# soc_aon_secure register map
Vendor: Texas Instruments
Peripheral module from a debugger description file (folder CC35X1).
Registers are 32-bit, access per field, reset 0x0 unless marked. A register's access mark holds for its fields unless they carry their own. Offsets are as the file gives them; lines under a group give offsets from that group; [hi:lo] are bit positions; {n}, {i} and the like mark numbered series; 'fields as' and 'values as' point back to an identical list; <NAME> marks a mode.

## soc_aon_secure (part 1 of 3)
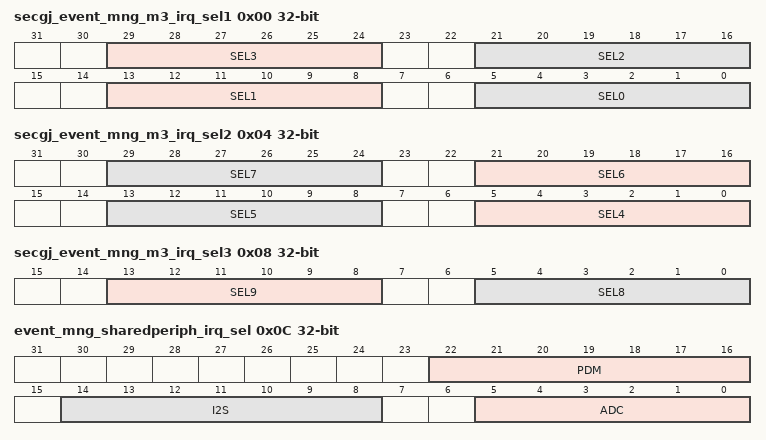
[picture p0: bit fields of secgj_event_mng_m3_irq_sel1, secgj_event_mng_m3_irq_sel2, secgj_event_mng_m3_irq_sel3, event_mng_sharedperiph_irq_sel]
0x00 secgj_event_mng_m3_irq_sel1 — M3 Event MUXs Selectors. One of three registers that contain selectors to M3 events. There are 10 event MUXs for M3. The selected event goes to ELP module as a wakeup event. INTERNAL NOTES: Event Manager DD - CORE 10 MUXs Selector Table [Confluence][https://confluence.itg.ti.com/display/WNG/Event+Manager+DD#EventManagerDD-CORE10MUXSelectorTable]
  [29:24] SEL3 rw — M3 Event Select Mux. This field selects 4th MUX output to M3 IRQ trough ELP as a wakeup event.
  [21:16] SEL2 rw — M3 Event Select Mux. This field selects 3rd MUX output to M3 IRQ trough ELP as a wakeup event.
  [13:8] SEL1 rw — M3 Event Select Mux. This field selects 2nd MUX output to M3 IRQ trough ELP as a wakeup event.
  [5:0] SEL0 rw — M3 Event Select Mux. This field selects 1st MUX output to M3 IRQ trough ELP as a wakeup event.
0x04 secgj_event_mng_m3_irq_sel2 — M3 Event MUXs Selectors. One of three registers that contain selectors to M3 events. There are 10 event MUXs for M3. The selected event goes to ELP module as a wakeup event. INTERNAL NOTES: Event Manager DD - CORE 10 MUXs Selector Table [Confluence][https://confluence.itg.ti.com/display/WNG/Event+Manager+DD#EventManagerDD-CORE10MUXSelectorTable]
  [8n-27:8n-32] SEL{n} rw (n=4..7) — M3 Event Select Mux. This field selects {n+1}th MUX output to M3 IRQ trough ELP as a wakeup event.
0x08 secgj_event_mng_m3_irq_sel3 — M3 Event MUXs Selectors. One of three registers that contain selectors to M3 events. There are 10 event MUXs for M3. The selected event goes to ELP module as a wakeup event. INTERNAL NOTES: Event Manager DD - CORE 10 MUXs Selector Table [Confluence][https://confluence.itg.ti.com/display/WNG/Event+Manager+DD#EventManagerDD-CORE10MUXSelectorTable]
  [13:8] SEL9 rw — M3 Event Select Mux. This field selects 10th MUX output to M3 IRQ trough ELP as a wakeup event.
  [5:0] SEL8 rw — M3 Event Select Mux. This field selects 9th MUX output to M3 IRQ trough ELP as a wakeup event.
0x0C event_mng_sharedperiph_irq_sel — Shared Peripherals Event MUXs Selectors. This register selects events to ADC, I2S and PDM. INTERNAL NOTE: Shared Peripherals selector table- [Confluence][https://confluence.itg.ti.com/display/WNG/Event+Manager+DD#EventManagerDD-SharedPeripheralsMUXSelectorTable]
  [22:16] PDM rw — PDM Event Selector. This field selects event to PDM. INTERNAL NOTE: PDM event selector table: [Confluence][https://confluence.itg.ti.com/display/WNG/Event+Manager+DD#EventManagerDD-PDMEventSelectorTable]
  [14:8] I2S rw — I2S Event Selector. This field selects event to I2S. INTERNAL NOTE: I2S event selector table: [Confluence][https://confluence.itg.ti.com/display/WNG/Event+Manager+DD#EventManagerDD-I2SEventSelectorTable]
  [5:0] ADC rw — ADC Event Selector. This field selects event to ADC. INTERNAL NOTE: ADC event selector table: [Confluence][https://confluence.itg.ti.com/display/WNG/Event+Manager+DD#EventManagerDD-ADCEventSelectorTable]
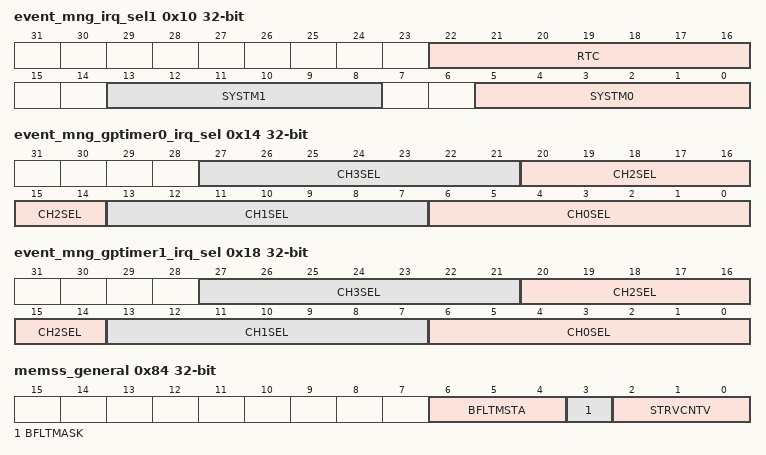
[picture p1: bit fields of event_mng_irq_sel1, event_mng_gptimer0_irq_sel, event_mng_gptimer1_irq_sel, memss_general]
0x10 event_mng_irq_sel1 — Timers Event MUXs Selectors. This register selects events to SYSTIMER and RTC. There are two MUXs of SYSTIMER and one for RTC.
  [22:16] RTC rw — RTC Event Selector. This field selects event to RTC. INTERNAL NOTE: RTC event selector table: [Confluence][https://confluence.itg.ti.com/display/WNG/Event+Manager+DD#EventManagerDD-RTCEventSelectorTable]
  [13:8] SYSTM1 rw — SYSTIMER Event 2nd Selector. This field selects event to SYSTIMER. INTERNAL NOTE: SYSTIMER event selector table: [Confluence][https://confluence.itg.ti.com/display/WNG/Event+Manager+DD#EventManagerDD-SysTimerEventSelectorTable]
  [5:0] SYSTM0 rw — SYSTIMER Event 1st Selector. This field selects event to SYSTIMER. INTERNAL NOTE: SYSTIMER event selector table: [Confluence][https://confluence.itg.ti.com/display/WNG/Event+Manager+DD#EventManagerDD-SysTimerEventSelectorTable]
0x14 event_mng_gptimer0_irq_sel — GPTIMER0 Channels Event MUXs Selectors. This register selects events to GPTIMER0. There are 4 event MUXs for GPTIMER Channels. INTERNAL NOTE: GPTIMER0 selector table- [Confluence][https://confluence.itg.ti.com/display/WNG/Event+Manager+DD#EventManagerDD-GPTIMER0EventSelectorTable]
  [7n+6:7n] CH{n}SEL rw (n=0..3) — This field selects MUX output to CH{n} of GPTIMER0 IRQ.
0x18 event_mng_gptimer1_irq_sel — GPTIMER1 Event MUXs Selectors. This register selects events to GPTIMER1. There are 4 event MUXs for GPTIMER Channels. INTERNAL NOTE: GPTIMER1 selector table- [Confluence][https://confluence.itg.ti.com/display/WNG/Event+Manager+DD#EventManagerDD-GPTIMER1EventSelectorTable]
  [7n+6:7n] CH{n}SEL rw (n=0..3) — This field selects MUX output to CH{n} of GPTIMER1 IRQ.
0x1C doorbell0_m2_clr — Doorbell 0 M33 Clear Register
  [0] CLR wo — M33 to clear the IRQ after handled the massage from M3. type : Write-Clear
0x20 doorbell0_m2_pulse — Doorbell 0 M33 Set Register.
  [0] SET wo — M33 to generate IRQ towards M3 after writing the message. type: Write-Clear
0x24 doorbell0_m2_lockbit — Doorbell 0 M33 Lock Bit.
  [1:0] LOCKBIT rw — Lock Bit. S/w attempt to lock upon read. if lock obtained, value set to 2 by h/w. M33 always looses to M3 Reading value: 0. not taken 1. taken by M3 2. taken by M33 (should wr IRQ afterwards) 3. invalid. generating the IRQ towards M3 clears the lock. Writing '00' also release the lock. '01' means lock obtained by receiver side Type: Write-Read-Clear
0x28 doorbell1_m2_clr — Doorbell 1 M33 Clear Register
  fields as doorbell0_m2_clr
0x2C doorbell1_m2_pulse — Doorbell 1 M33 Set Register.
  fields as doorbell0_m2_pulse
0x30 doorbell1_m2_lockbit — Doorbell 1 M33 Lock Bit.
  fields as doorbell0_m2_lockbit
0x34 doorbell4_m2_clr — Doorbell 4 M33 Clear Register
  fields as doorbell0_m2_clr
0x38 doorbell4_m2_pulse — Doorbell 4 M33 Set Register.
  fields as doorbell0_m2_pulse
0x3C doorbell4_m2_lockbit — Doorbell 4 M33 Lock Bit.
  fields as doorbell0_m2_lockbit
0x40 doorbell5_m2_clr — Doorbell 5 M33 Clear Register
  fields as doorbell0_m2_clr
0x44 doorbell5_m2_pulse — Doorbell 5 M33 Set Register.
  fields as doorbell0_m2_pulse
0x48 doorbell5_m2_lockbit — Doorbell 5 M33 Lock Bit.
  fields as doorbell0_m2_lockbit
0x4C secgr_cmem_int_addr_start reset not defined — CODE Memory MEMSS Start Address. CMEM Start Address-also define S/NS region split. split is in 1k resolution
  [31:12] ADDR rw — CMEM Start Address-also define S/NS region split. split is in 1k resolution
0x50 secgr_cmem_int_addr_end reset not defined — CODE Memory MEMSS End Address. CMEM end Address-also define S/NS region split
  [31:12] ADDR rw — CMEM end Address-also define S/NS region split
0x54 secgr_dmem_int_addr_start reset not defined — DATA Memory MEMSS Start Address. DMEM Start Address-also define S/NS region split
  [31:12] ADDR rw — DMEM Start Address-also define S/NS region split
0x58 secgr_dmem_int_addr_end reset not defined — DATA Memory MEMSS End Address. DMEM end Address-also define S/NS region split
  [31:12] ADDR rw — DMEM end Address-also define S/NS region split
0x64 secgr_tcm_data_int_addr_start reset not defined — TCM DATA Memory MEMSS Start Address. TCM data Start Address-also define S/NS region split
  [31:10] ADDR rw — TCM data Start Address-also define S/NS region split
0x68 secgr_tcm_data_int_addr_end reset not defined — TCM DATA Memory MEMSS End Address. TCM data end Address-also define S/NS region split
  [31:10] ADDR rw — TCM data end Address-also define S/NS region split
0x7C secured_gpio_evt_sts_0 ro — Secured GPIO Event Status, 1st Register. 45 bits status over two registers.
  [31:0] STA31TO0 — Secured event status , first 32 bits. ([31:0])
0x80 secured_gpio_evt_sts_1 ro — Secured GPIO Event Status, 2nd Register. 45 bits status over two registers.
  [12:0] STA44TO32 — Secured event status , 13 MSBs. ([44:32])
0x84 memss_general — MEMSS General Control Register. This register controls starvation mechanism counter value and MEMSS bus fault mask.
  [6:4] BFLTMSTA ro — Bus Fault Masked Status. Out of Memory Index: 0. No error 1. M33 Code 2. M33 Data #1 + #2 3. M3 Code 4. M3 Data 5. M3 PRAM 6. BLE Code 7. Global OCP
  [3] BFLTMASK rw — MEMSS Bus Fault Mask 1. Mask 0. Do not mask
  [2:0] STRVCNTV rw — Starvation Counter Value Configuration. That value reflect how long writing to mailbox can be delayed.
0x88 memss_bus_fault_raw_status ro — MEMSS General Control Register. This is a status register for bus fault raw status.
  [2:0] BFLTRWSTA — Bus Fault Raw Status. Error indication from memss. Out of Memory Index: 0. No error 1. M33 Code 2. M33 Data #1 + #2 3. M3 Code 4. M3 Data 5. M3 PRAM 6. BLE Code 7. Global OCP Type: Read-Clear
0x90 spare — Spare Register. This is a spare register in M33S aperture.
  [3:0] BF rw — Spare Field. Non-locked , M33S aperture.
0x9C secgt_vtor_s — M33 Secure Vector Table Base Address.
  [31:7] ADDR rw — init VTOR Secured Address.
0xA0 secgu_vtor_ns — M33 Non-Secure Vector Table Base Address.
  [31:7] ADDR rw — init VTOR non Secured address
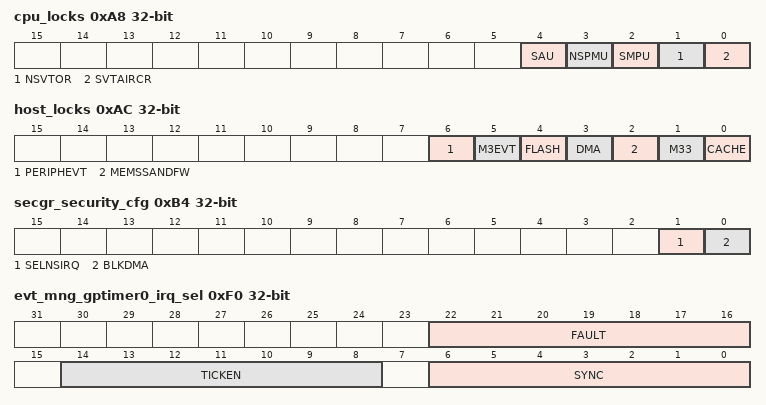
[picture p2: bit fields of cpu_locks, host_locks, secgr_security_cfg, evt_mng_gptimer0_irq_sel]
0xA8 cpu_locks — CPU Locks. This register contain 5 locks. Issued to M33 Cortex and used to lock internal cortex registers. LOCKSVTAIRCR, LOCKNSVTOR, LOCKSMPU, LOCKNSMPU, LOCKSAU.
  [4] SAU rw — Locking this Cortex internal configuration
  [3] NSPMU rw — Locking this Cortex internal configuration
  [2] SMPU rw — Locking this Cortex internal configuration
  [1] NSVTOR rw — Locking this Cortex internal configuration
  [0] SVTAIRCR rw — Locking this Cortex internal configuration
0xAC host_locks access not given — Host Lock Signals. lock once. Do Not lock until written. When written Locked immediately, cleared only at soc aon reset or por reset. These are host security lock configurations (some can be also locked by TI)
  [6] PERIPHEVT — Locking the firewall configurations of: HIF, CORE, CORE AON, HSM, shared Periphs
  [5] M3EVT — Locking the configurations of M3 Events
  [4] FLASH — Locking the configurations of On The Fly Enc/Decryption Module Region Related Registers (four registers per region, four regions)
  [3] DMA — Locking the configurations of System DMA
  [2] MEMSSANDFW — Locking the configurations of Memory Sub System
  [1] M33 — Locking the configurations of Host MCU, both Secured and non Secured
  [0] CACHE — Locking the configurations of ICACHE
0xB0 host_boot_done access not given — Host Boot Done 1 lock. Write once. Asserted by FW by the end of soc boot done Or in elevated mode By either by TI of by the host and indicates device exit from secure boot mode. this signal also locks host security configurations , Locked immediately , cleared only at soc aon reset or por reset
  [0] DONE — Locking host security configurations
0xB4 secgr_security_cfg — Security Configurations.
  [1] SELNSIRQ rw — This field determine whether the 4 SW interrupts MSbits will be owned by secured/non secured. 0. Non-Secured 1. Secured
  [0] BLKDMA rw — This Field blocks the uDMA transactions to CMEM. 0. un-Block 1. Block
0xB8 db_m33_sec_imask reset 0xFFFF0 (reset mask 0xFFFFFFF0) — Doorbell M33 Secured IMASK. Mask Event. 0. CLR - Clear Interrupt Mask 1. SET - Set Interrupt Mask
  [3:0] IMASK rw — Bits division to events: bit [3] - doorbell 5 M3 IRQ bit [2] - doorbell 4 M3 IRQ bit [1] - doorbell 1 M3 IRQ bit [0] - doorbell 0 M3 IRQ
0xBC db_m33_sec_iset_evt_mng — Doorbell M33 Secured ISET. Sets event in RIS Write 0 - NO_EFFECT - Writing 0 has no effect Write 1 - SET - Sets interrupt
  [3:0] ISET wo — Bits division to events: bit [3] - doorbell 5 M3 IRQ bit [2] - doorbell 4 M3 IRQ bit [1] - doorbell 1 M3 IRQ bit [0] - doorbell 0 M3 IRQ Type: Write-Clear
0xC0 db_m33_sec_iclr_evt_mng — Doorbell M33 Secured ICLR. Clears event in RIS Write 0 - NO_EFFECT - Writing 0 has no effect Write 1 - CLR - Clears the Event
  [3:0] ICLR wo — Bits division to events: bit [3] - doorbell 5 M3 IRQ bit [2] - doorbell 4 M3 IRQ bit [1] - doorbell 1 M3 IRQ bit [0] - doorbell 0 M3 IRQ Type: Write-Clear
0xC4 db_m33_sec_imset_evt_mng — Doorbell M33 Secured IMSET. Sets Event Write 0 - NO_EFFECT - Writing 0 has no effect Write 1 - SET - Set interrupt mask
  [3:0] IMSET wo — Bits division to events: bit [3] - doorbell 5 M3 IRQ bit [2] - doorbell 4 M3 IRQ bit [1] - doorbell 1 M3 IRQ bit [0] - doorbell 0 M3 IRQ Type: Write-Clear
0xC8 db_m33_sec_imclr_evt_mng — Doorbell M33 Secured IMCLR. Clears Event Write 0 - NO_EFFECT - Writing 0 has no effect Write 1 - CLR - Clear interrupt mask
  [3:0] IMCLR wo — Bits division to events: bit [3] - doorbell 5 M3 IRQ bit [2] - doorbell 4 M3 IRQ bit [1] - doorbell 1 M3 IRQ bit [0] - doorbell 0 M3 IRQ Type: Write-Clear
0xCC db_m33_sec_ris_evt_mng ro — Doorbell M33 Secured RIS. Raw interrupt status for event. This bit is set to 1 when an event is received. when the corresponding bit in ICLR is set to 1, this bit will be cleared. Read 0 - CLR - Interrupt did not occur Read 1 - SET - Interrupt occurred
  [3:0] RIS — Bits division to events: bit [3] - doorbell 5 M3 IRQ bit [2] - doorbell 4 M3 IRQ bit [1] - doorbell 1 M3 IRQ bit [0] - doorbell 0 M3 IRQ
0xD0 db_m33_sec_mis_evt_mng ro — Doorbell M33 Secured MIS. Mask interrupt status for event Read 0 - CLR - Interrupt did not occur Read 1 - SET - Interrupt occurred
  [3:0] MIS — Bits division to events: bit [3] - doorbell 5 M3 IRQ bit [2] - doorbell 4 M3 IRQ bit [1] - doorbell 1 M3 IRQ bit [0] - doorbell 0 M3 IRQ
0xD4 error_m33_sec_imask reset 0xFFFF — M33 Secured Error IMASK. Mask Event. '0' - CLR - Clear Interrupt Mask '1' - SET - Set Interrupt Mask
  [7:0] IMASK rw — Bits division to events: bit[7] - CORE ELP WATCHDOG Timer bit[6:4] - SOC IC IRQs bit[3] - CORE to SDIO WATCHDOG bit[2] - PLL Unlock bit[1] - MEMss bus fault bit[0] - HSM fatal error
0xD8 error_m33_sec_iset_evt_mng — M33 Secured Error ISET. Sets event in RIS Write 0 - NO_EFFECT - Writing 0 has no effect Write 1 - SET - Sets interrupt
  [7:0] ISET wo — Bits division to events: bit[7] - CORE ELP WATCHDOG Timer bit[6:4] - SOC IC IRQs bit[3] - CORE to SDIO WATCHDOG bit[2] - PLL Unlock bit[1] - MEMss bus fault bit[0] - HSM fatal error Type: Write-Clear
0xDC error_m33_sec_iclr_evt_mng — M33 Secured Error ICLR. Clears event in RIS Write 0 - NO_EFFECT - Writing 0 has no effect Write 1 - CLR - Clears the Event
  [7:0] ICLR wo — Bits division to events: bit[7] - CORE ELP WATCHDOG Timer bit[6:4] - SOC IC IRQs bit[3] - CORE to SDIO WATCHDOG bit[2] - PLL Unlock bit[1] - MEMss bus fault bit[0] - HSM fatal error Type: Write-Clear
0xE0 error_m33_sec_imset_evt_mng — M33 Secured Error IMSET. Sets Event Write 0 - NO_EFFECT - Writing 0 has no effect Write 1 - SET - Set interrupt mask
  [7:0] IMSET wo — Bits division to events: bit[7] - CORE ELP WATCHDOG Timer bit[6:4] - SOC IC IRQs bit[3] - CORE to SDIO WATCHDOG bit[2] - PLL Unlock bit[1] - MEMss bus fault bit[0] - HSM fatal error Type: Write-Clear
0xE4 error_m33_sec_imclr_evt_mng — M33 Secured Error IMCLR. Clears Event Write 0 - NO_EFFECT - Writing 0 has no effect Write 1 - CLR - Clear interrupt mask
  [7:0] IMCLR wo — Bits division to events: bit[7] - CORE ELP WATCHDOG Timer bit[6:4] - SOC IC IRQs bit[3] - CORE to SDIO WATCHDOG bit[2] - PLL Unlock bit[1] - MEMss bus fault bit[0] - HSM fatal error Type: Write-Clear
0xE8 error_m33_sec_ris_evt_mng ro — M33 Secured Error RIS. Raw interrupt status for event. This bit is set to 1 when an event is received. when the corresponding bit in ICLR is set to 1, this bit will be cleared. Read 0 - CLR - Interrupt did not occur Read 1 - SET - Interrupt occurred
  [7:0] RIS — Bits division to events: bit[7] - CORE ELP WATCHDOG Timer bit[6:4] - SOC IC IRQs bit[3] - CORE to SDIO WATCHDOG bit[2] - PLL Unlock bit[1] - MEMss bus fault bit[0] - HSM fatal error
0xEC error_m33_sec_mis_evt_mng ro — M33 Secured Error MIS. Mask interrupt status for event Read 0 - CLR - Interrupt did not occur Read 1 - SET - Interrupt occurred
  [7:0] MIS — Bits division to events: bit[7] - CORE ELP WATCHDOG Timer bit[6:4] - SOC IC IRQs bit[3] - CORE to SDIO WATCHDOG bit[2] - PLL Unlock bit[1] - MEMss bus fault bit[0] - HSM fatal error
0xF0 evt_mng_gptimer0_irq_sel — GPTIMER0 Sync, Tick Enable and Fault Event MUXs Selectors. This register selects events to GPTIMER0. INTERNAL NOTE: GPTIMER0 selector table- [Confluence][https://confluence.itg.ti.com/display/WNG/Event+Manager+DD#EventManagerDD]
  [22:16] FAULT rw — Selects fault MUX output to GPTIMER0 IRQ
  [14:8] TICKEN rw — Selects tick enable MUX output to GPTIMER0 IRQ
  [6:0] SYNC rw — Selects sync MUX output to GPTIMER0 IRQ
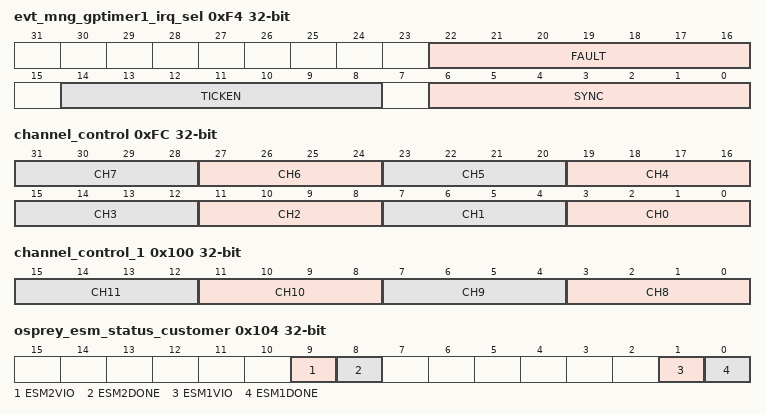
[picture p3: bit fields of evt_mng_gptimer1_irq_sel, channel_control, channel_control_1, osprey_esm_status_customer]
0xF4 evt_mng_gptimer1_irq_sel — GPTIMER1 Sync, Tick Enable and Fault Event MUXs Selectors. This register selects events to GPTIMER1. INTERNAL NOTE: GPTIMER0 selector table- [Confluence][https://confluence.itg.ti.com/display/WNG/Event+Manager+DD#EventManagerDD]
  fields as evt_mng_gptimer0_irq_sel
0xFC channel_control rw — Host DMA Channel Controlled by Defined Peripheral. The value of each fields concats with [HOST_DMA:JOBCTLCHx.SRCDSTCFG] (when x is channel num) if [CHCTL0.CHx] = 4 and [JOBCTLCHx.SRCDSTCFG] = 1 (value = 0100_1 = 9) then flow control signals of channel x are connected to periph number 9 flow control signals
  [4n+3:4n] CH{n} (n=0..7) — Channel {n} Control. Flow control signals: 22 HIF 21 Not Valid - PDM has only read 20 PDM 19 Not Valid - ADC has only read 18 ADC 17 MCAN 1 16 MCAN 0 15 SDIO TX 14 SDIO RX 13 SDMMC TX 12 SDMMC RX 11 I2C TX 10 I2C RX 9 I2C TX 8 I2C RX 7 SPI TX 6 SPI RX 5 SPI TX 4 SPI RX 3 UART TX 2 UART RX 1 UART TX 0 UART RX
0x100 channel_control_1 — Host DMA Channel Controlled by Defined Peripheral. The value of each fields concats with [HOST_DMA:JOBCTLCHx.SRCDSTCFG] (when x is channel num) if [CHCTL1.CHx] = 4 and [JOBCTLCHx.SRCDSTCFG] = 1 (value = 0100_1 = 9) then flow control signals of channel x are connected to periph number 9 flow control signals
  [4n-29:4n-32] CH{n} rw (n=8..11) — Channel {n} Control. Flow control signals: 22 HIF 21 Not Valid - PDM has only read 20 PDM 19 Not Valid - ADC has only read 18 ADC 17 MCAN 1 16 MCAN 0 15 SDIO TX 14 SDIO RX 13 SDMMC TX 12 SDMMC RX 11 I2C TX 10 I2C RX 9 I2C TX 8 I2C RX 7 SPI TX 6 SPI RX 5 SPI TX 4 SPI RX 3 UART TX 2 UART RX 1 UART TX 0 UART RX
0x104 osprey_esm_status_customer ro — Customer ESMs Status. status register , for each of the ESM (enable sequence monitor) what is the status (Done, violated, or None) Final ESM status for the entire ESM - ESM machine + magic value comparators
  [9] ESM2VIO — This field indicates that ESM1 is violated.
  [8] ESM2DONE — This field indicates that ESM2 is done.
  [1] ESM1VIO — This field indicates that ESM1 is violated.
  [0] ESM1DONE — This field indicates that ESM1 is done.
0x10C secgg_memss_cfg — MEMSS Configurations. Supported Memory configurations: Functional Modes: 0x0. Baseline 0x1. Extended M3 0x2. Extended throughput 0x3. Extended throughput + WIFI features 0x4. Extended Host Execution 0x5. Extended M33 Data Debug Modes (OCLA Memory): 0x6. Core debug (<M33 Data) 0x7. Core debug Extended throughput (<M33 Data <M3 Exec) 0x8. Core debug PHY only (<M3,M33 Data) 0x9. Host debug (<M3 Exec) 0xA. Host debug extended Host Execution 0xB. Host debug extended M33 Data
  [3:0] MODE rw — MEMSS mode of bank ownership
0x138 secured_gpio_mis_0 ro — Secured Gpio MIS.
  [31:0] _31TO0 — 32 LSBs of MIS. (45 Total)
0x13C secured_gpio_mis_1 ro — Secured Gpio MIS.
  [12:0] _44TO32 — 13 MSBs of MIS. (45 Total)
0x140 secured_gpio_func_0 rw — Secured GPIO Functional Mask. 0. Mask 1. Un-Mask
  [31:0] MASK31TO0 — 32 LSBs of MASK. (45 Total)
0x144 secured_gpio_func_1 — Secured GPIO Functional Mask. 0. Mask 1. Un-Mask
  [12:0] MASK44TO32 rw — 13 MSBs of MASK. (45 Total)
0x148 m33s_spare — Spare Reg, M33S Aperture. non-locked.
  [3:0] BF rw — M33S spare register. not locked.
0x14C secgk_esm1_2nd_magic_val — ESM1 2nd Magic Value. This value is compared to hard coded value and unmask ESM only when value is matched. This additional compare allow additional protection on ESM and also allow vendor to unmask ESM only at the end of vendor secure boot (SBL) is completed
  [7:0] MGCVAL rw — ESM 2nd magic value
0x150 secgk_esm2_2nd_magic_val — ESM2 2nd Magic Value. This value is compared to hard coded value and unmask ESM only when value is matched. This additional compare allow additional protection on ESM and also allow vendor to unmask ESM only at the end of vendor secure boot (SBL) is completed
  [7:0] MGCVAL rw — ESM 2nd magic value
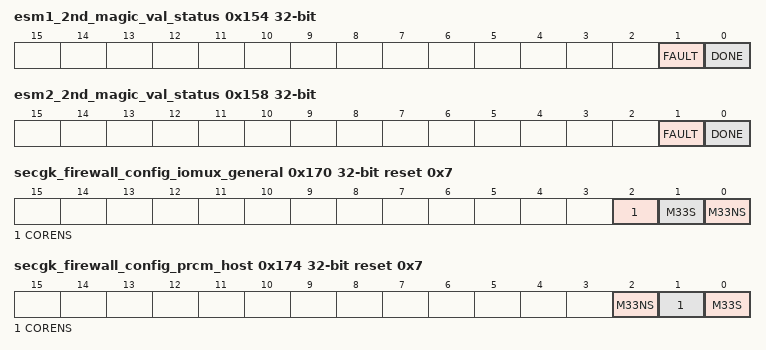
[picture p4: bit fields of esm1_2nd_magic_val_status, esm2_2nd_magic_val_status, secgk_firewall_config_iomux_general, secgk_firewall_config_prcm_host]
0x154 esm1_2nd_magic_val_status ro — ESM1 2nd Magic Value Status. ESM magic value match indication.
  [1] FAULT — ESM 2nd magic val fault ( note: indicates fault before a write to the magic val register)
  [0] DONE — ESM 2nd magic val match
0x158 esm2_2nd_magic_val_status ro — ESM2 2nd Magic Value. ESM magic value match indication.
  fields as esm1_2nd_magic_val_status
0x15C secgk_firewall_config_host_bypass reset 0x1 — HOST FW Bypass.
  [0] BYPASS rw — bypass the following module's firewall configuration: IOMUX_COMMON_SEL PRCM_AON_HOST PRCM_AON_COMMON SCRATCHPAD PLLSHARING SOC_IC SOC_AON_M33_S SOC_AON_M33_NS SOC_AAON_M33_S SOC_AAON_M33_NS RTC XIP_OSPI XIP_OSPI_INDAC XIP_GENERAL XIP_UDMA_SEC XIP_UDMA_NON_SEC OTFDE_REGION0-3 HOST_DMA_GENERAL_CFG
0x160 secgk_firewall_config_dma_bypass reset 0x1 — DMA FW BYPASS
  [0] BYPASS rw — Bypass the firewall configuration for HOST_DMA module
0x164 secgk_firewall_config_peripherals_bypass reset 0x1 — Peripheral Firewall Bypass.
  [0] BYPASS rw — bypass the following module's firewall configuration: HIF HSM CORE_AON I2C0/1 SPI0/1 UART0/1 GPTIMER0/1 I2S PDM CAN ADC SDMMC SDIO
0x168 secgk_firewall_config_m33_bypass reset 0x1 — HOST MCU Firewall Bypass
  [0] BYPASS rw — bypass the firewall configuration for HOST MCU module.
0x16C secgk_firewall_config_memss_bypass reset 0x1 — MEMSS Firewall Bypass
  [0] BYPASS rw — bypass the Firewall configuration for MEMSS module.
0x170 secgk_firewall_config_iomux_general reset 0x7 — IOMUX General firewall access permission for 3 controller id : 0 - M33 Non Secured 1 - M33 Secured 2 - Core (Non Secure)
  [2] CORENS rw — Controller Core Non Secured: '0' - access not allowed '1' - access allowed
  [1] M33S rw — Controller M33 Secured: '0' - access not allowed '1' - access allowed
  [0] M33NS rw — Controller M33 None Secured: '0' - access not allowed '1' - access allowed
0x174 secgk_firewall_config_prcm_host reset 0x7 — PRCM_HOST firewall access permission for 3 controller id : 0 - M33 Non Secured 1 - M33 Secured 2 - Core (Non Secure)
  [2] M33NS rw — Controller M33 None Secured: '0' - access not allowed '1' - access allowed
  [1] CORENS rw — Controller Core Non Secured: '0' - access not allowed '1' - access allowed
  [0] M33S rw — Controller M33 Secured: '0' - access not allowed '1' - access allowed
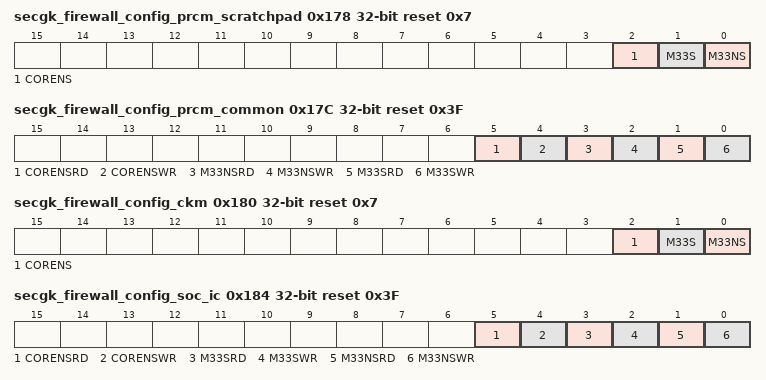
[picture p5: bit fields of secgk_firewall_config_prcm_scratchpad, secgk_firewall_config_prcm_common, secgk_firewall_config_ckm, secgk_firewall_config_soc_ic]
0x178 secgk_firewall_config_prcm_scratchpad reset 0x7 — M33 SCRATCHPAD firewall access permission for 3 controller id : 0 - M33 Non Secured 1 - M33 Secured 2 - Core (Non Secure)
  fields as secgk_firewall_config_iomux_general
0x17C secgk_firewall_config_prcm_common reset 0x3F — PRCM_COMMON firewall access permission for 3 controller id : 0 - M33 Non Secured 1 - M33 Secured 2 - Core (Non Secure)
  [5] CORENSRD rw — Controller Core Non Secured: '0' - access not allowed '1' - access allowed
  [4] CORENSWR rw — Controller Core Non Secured: '0' - access not allowed '1' - access allowed
  [3] M33NSRD rw — Controller M33 None Secured: '0' - access not allowed '1' - access allowed
  [2] M33NSWR rw — Controller M33 None Secured: '0' - access not allowed '1' - access allowed
  [1] M33SRD rw — Controller M33 Secured: '0' - access not allowed '1' - access allowed
  [0] M33SWR rw — Controller M33 Secured: '0' - access not allowed '1' - access allowed
0x180 secgk_firewall_config_ckm reset 0x7 — CKM firewall access permission for 3 controller id : 0 - M33 Non Secured 1 - M33 Secured 2 - Core (Non Secure)
  fields as secgk_firewall_config_iomux_general
0x184 secgk_firewall_config_soc_ic reset 0x3F — SOC_IC firewall access permission for 3 controller id : 0 - M33 Non Secured 1 - M33 Secured 2 - Core (Non Secure)
  [5] CORENSRD rw — Controller Core Non Secured: '0' - access not allowed '1' - access allowed
  [4] CORENSWR rw — Controller Core Non Secured: '0' - access not allowed '1' - access allowed
  [3] M33SRD rw — Controller M33 Secured: '0' - access not allowed '1' - access allowed
  [2] M33SWR rw — Controller M33 Secured: '0' - access not allowed '1' - access allowed
  [1] M33NSRD rw — Controller M33 None Secured: '0' - access not allowed '1' - access allowed
  [0] M33NSWR rw — Controller M33 None Secured: '0' - access not allowed '1' - access allowed
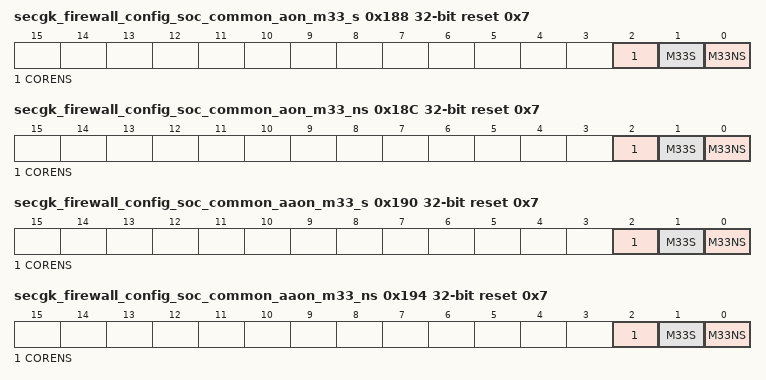
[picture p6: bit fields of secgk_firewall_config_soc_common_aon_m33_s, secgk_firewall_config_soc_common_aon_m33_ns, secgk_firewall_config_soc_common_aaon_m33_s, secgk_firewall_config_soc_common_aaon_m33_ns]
0x188 secgk_firewall_config_soc_common_aon_m33_s reset 0x7 — AON_M33_S firewall access permission for 3 controller id : 0 - M33 Non Secured 1 - M33 Secured 2 - Core (Non Secure)
  fields as secgk_firewall_config_iomux_general
0x18C secgk_firewall_config_soc_common_aon_m33_ns reset 0x7 — AON_M33_NS firewall access permission for 3 controller id : 0 - M33 Non Secured 1 - M33 Secured 2 - Core (Non Secure)
  fields as secgk_firewall_config_iomux_general
0x190 secgk_firewall_config_soc_common_aaon_m33_s reset 0x7 — AAON_M33_S firewall access permission for 3 controller id : 0 - M33 Non Secured 1 - M33 Secured 2 - Core (Non Secure)
  fields as secgk_firewall_config_iomux_general
0x194 secgk_firewall_config_soc_common_aaon_m33_ns reset 0x7 — AAON_M33_NS firewall access permission for 3 controller id : 0 - M33 Non Secured 1 - M33 Secured 2 - Core (Non Secure)
  fields as secgk_firewall_config_iomux_general
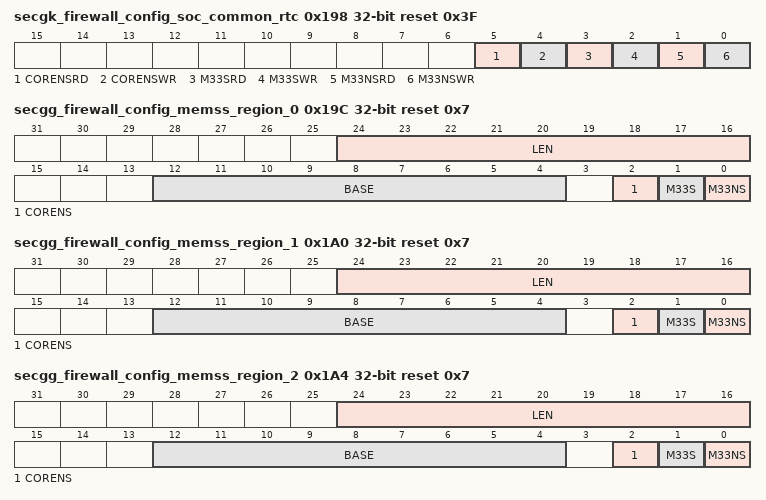
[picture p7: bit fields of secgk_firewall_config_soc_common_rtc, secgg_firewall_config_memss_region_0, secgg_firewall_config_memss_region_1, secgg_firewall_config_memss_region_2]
0x198 secgk_firewall_config_soc_common_rtc reset 0x3F — RTC firewall access permission for 3 controller id : 0 - M33 Non Secured 1 - M33 Secured 2 - Core (Non Secure)
  fields as secgk_firewall_config_soc_ic
0x19C secgg_firewall_config_memss_region_0 reset 0x7 — MEMSS region 0 firewall access permission for 3 controller id : 0 - M33 Non Secured (valid only in privilege mode) 1 - M33 Secured (valid only in privilege mode) 2 - Core (Non Secure) MEMSS address space: 0x41C00000 - 0x41DFFFFF for Memss the base address for security firewalls is 0x41c78000 ( M33 Data Ram from global port access) max window size is 512Kb
  [24:16] LEN rw — address base with 1K granularity : address base len for firewall is the offset from the region's base address indicated in the same region field describing the end of a firewall window that has a certain access rules (R/W Permission) for each controller-id MEMSS address space: 0x41C00000 - 0x41DFFFFF for Memss the base address for security firewalls is 0x41c78000 ( M33 Data Ram from global port access) max window size is 512Kb example: worker base address: 0x41C00000 current address to access: 0x41C01514 region_base_address: 0x4 region_base_address_len: 0x2 --> (region_base_address + region_base_address_len) --> 0x4+0x2 -->0x6 0x41C01514 --> ((0x41C01514 - 0x41C00000) >> 10) -->0x5 0x4 <= 0x5 < 0x6 that address falls on the region window and therefor obeys to that region set of access rules
  [12:4] BASE rw — address base with 1K granularity : address base for firewall is the the offset start address from a worker base address describing the beginning of a firewall window that has a certain access rules (R/W Permission) for each controller-id MEMSS address space: 0x41C00000 - 0x41DFFFFF for Memss the base address for security firewalls is 0x41c78000 ( M33 Data Ram from global port access) max window size is 512Kb example: worker base address: 0x41C78000 current address to access: 0x41C78504 region_base_address: 0x1 region_base_address_len: 0x1 0x41C78504 --> ((0x41C78504 - 0x41C78000) >> 10) --> 0x1 0x1(base) <= 0x1(current) < 0x1(base)+0x1(len) that address falls on the region window and therefor obeys to that region set of access rules
  [2] CORENS rw — Controller Core Non Secured: '0' - access not allowed '1' - access allowed
  [1] M33S rw — Controller M33 Secured: (valid only in privilege mode) '0' - access not allowed '1' - access allowed
  [0] M33NS rw — Controller M33 None Secured: (valid only in privilege mode) '0' - access not allowed '1' - access allowed
0x1A0 secgg_firewall_config_memss_region_1 reset 0x7 — MEMSS region 1 firewall access permission for 3 controller id : 0 - M33 Non Secured (valid only in privilege mode) 1 - M33 Secured (valid only in privilege mode) 2 - Core (Non Secure) MEMSS address space: 0x41C00000 - 0x41DFFFFF for Memss the base address for security firewalls is 0x41c78000 ( M33 Data Ram from global port access) max window size is 512Kb
  fields as secgg_firewall_config_memss_region_0
0x1A4 secgg_firewall_config_memss_region_2 reset 0x7 — MEMSS region 2 firewall access permission for 3 controller id : 0 - M33 Non Secured (not in use - avoid M33 access MEMSS) 1 - M33 Secured (not in use - avoid M33 access MEMSS) 2 - Core (Non Secure) MEMSS address space: 0x41C00000 - 0x41DFFFFF for Memss the base address for security firewalls is 0x41c78000 ( M33 Data Ram from global port access) max window size is 512Kb
  [24:16] LEN rw — address base with 1K granularity : address base len for firewall is the offset from the region's base address indicated in the same region field describing the end of a firewall window that has a certain access rules (R/W Permission) for each controller-id MEMSS address space: 0x41C00000 - 0x41DFFFFF for Memss the base address for security firewalls is 0x41c78000 ( M33 Data Ram from global port access) max window size is 512Kb example: worker base address: 0x41C00000 current address to access: 0x41C01514 region_base_address: 0x4 region_base_address_len: 0x2 --> (region_base_address + region_base_address_len) --> 0x4+0x2 -->0x6 0x41C01514 --> ((0x41C01514 - 0x41C00000) >> 10) -->0x5 0x4 <= 0x5 < 0x6 that address falls on the region window and therefor obeys to that region set of access rules
  [12:4] BASE rw — address base with 1K granularity : address base for firewall is the the offset start address from a worker base address describing the beginning of a firewall window that has a certain access rules (R/W Permission) for each controller-id MEMSS address space: 0x41C00000 - 0x41DFFFFF for Memss the base address for security firewalls is 0x41c78000 ( M33 Data Ram from global port access) max window size is 512Kb example: worker base address: 0x41C78000 current address to access: 0x41C78504 region_base_address: 0x1 region_base_address_len: 0x1 0x41C78504 --> ((0x41C78504 - 0x41C78000) >> 10) --> 0x1 0x1(base) <= 0x1(current) < 0x1(base)+0x1(len) that address falls on the region window and therefor obeys to that region set of access rules
  [2] CORENS rw — Controller Core Non Secured: '0' - access not allowed '1' - access allowed
  [1] M33S rw — Controller M33 Secured: (valid only in privilege mode) '0' - access not allowed '1' - access allowed
  [0] M33NS rw — Controller M33 non Secured: (valid only in privilege mode) '0' - access not allowed '1' - access allowed
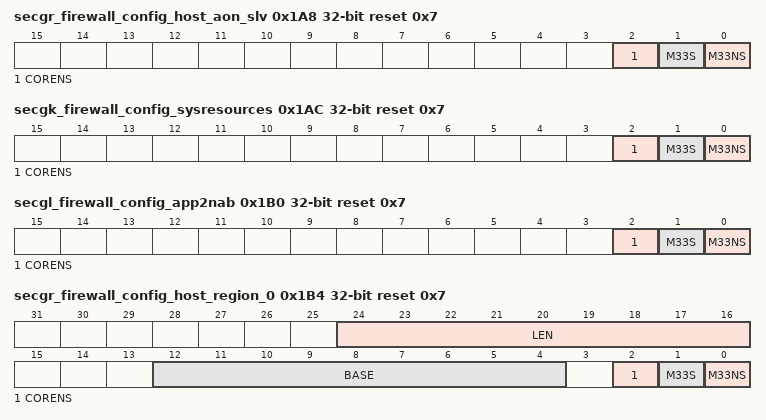
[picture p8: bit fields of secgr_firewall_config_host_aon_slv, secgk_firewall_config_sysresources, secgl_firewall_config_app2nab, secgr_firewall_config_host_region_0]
0x1A8 secgr_firewall_config_host_aon_slv reset 0x7 — HOST_AON_SLV firewall access permission for 3 controller id : 0 - M33 Non Secured 1 - M33 Secured 2 - Core (Non Secure)
  fields as secgk_firewall_config_iomux_general
0x1AC secgk_firewall_config_sysresources reset 0x7 — SYSRESOURCES firewall access permission for 3 controller id : 0 - M33 Non Secured 1 - M33 Secured 2 - Core (Non Secure)
  fields as secgk_firewall_config_iomux_general
0x1B0 secgl_firewall_config_app2nab reset 0x7 — HIF firewall access permission for 3 controller id : 0 - M33 Non Secured 1 - M33 Secured 2 - Core (Non Secure)
  fields as secgk_firewall_config_iomux_general
0x1B4 secgr_firewall_config_host_region_0 reset 0x7 — HOST MCU region 0 firewall access permission for 3 controller id : 0 - M33 Non Secured 1 - M33 Secured 2 - Core (Non Secure)
  [24:16] LEN rw — address base with 1K granularity : address base len for firewall is the offset from the region's base address indicated in the same region field describing the end of a firewall window that has a certain access rules (R/W Permission) for each controller-id HOST_MCU_REGION_0 address space: 0x20000000 - 0x2FFFFFFF HOST_MCU_REGION_0 base_len can range from: ##register base_len value## 0x0 - 0x7F for HOST_MCU_REGION_0 the base address for security firewalls is 0x20000000 ( HOST_MCU_REGION_0 ) max window size is 128Kb example: worker base address: 0x20000000 current address to access: 0x20001504 region_base_address: 0x4 region_base_address_len: 0x2 --> (region_base_address + region_base_address_len) --> 0x4+0x2 -->0x6 0x20001504 --> ((0x20001504 - 0x20000000) >> 10) -->0x4 0x4 <= 0x5 < 0x6 that address falls on the region window and therefor obeys to that region set of access rules
  [12:4] BASE rw — address base with 1K granularity : address base for firewall is the the offset start address from a worker base address describing the beginning of a firewall window that has a certain access rules (R/W Permission) for each controller-id HOST_MCU address space: 0x00000000 - 0x2FFFFFFF / 0x41900000 - 0x4190FFFF HOST_MCU_REGION_0 is assigned to TCM DATA RAM HOST_MCU_REGION_0 base address can range from: ##register base value## 0x0 - 0x7F ##absolute equivalent value## 0x200000000 - 0x20001FFFF for HOST_MCU_REGION_0 the base address for security firewalls is 0x200000000 ( M33 TCM Data RAM ) max window size is 128Kb example: worker base address: 0x200000000 current address to access: 0x20000504 region_base_address: 0x1 region_base_address_len: 0x1 0x20000504 --> ((0x20000504 - 0x200000000) >> 10) --> 0x1 0x1(base) <= 0x1(current) < 0x1(base)+0x1(len) that address falls on the region window and therefor obeys to that region set of access rules
  [2] CORENS rw — Controller Core Non Secured: '0' - access not allowed '1' - access allowed
  [1] M33S rw — Controller M33 Secured: '0' - access not allowed '1' - access allowed
  [0] M33NS rw — Controller M33 None Secured: '0' - access not allowed '1' - access allowed
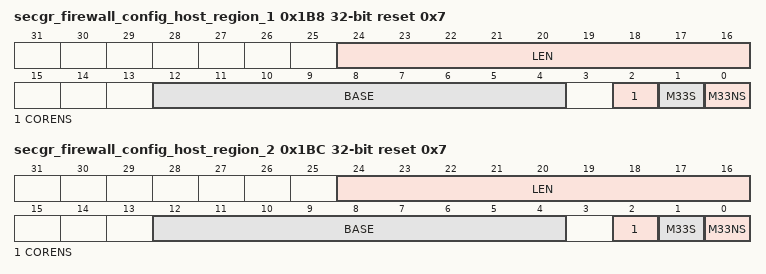
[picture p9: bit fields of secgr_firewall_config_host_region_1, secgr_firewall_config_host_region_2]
0x1B8 secgr_firewall_config_host_region_1 reset 0x7 — HOST MCU region 1 firewall access permission for 3 controller id : 0 - M33 Non Secured 1 - M33 Secured 2 - Core (Non Secure)
  [24:16] LEN rw — address base with 1K granularity : address base len for firewall is the offset from the region's base address indicated in the same region field describing the end of a firewall window that has a certain access rules (R/W Permission) for each controller-id HOST_MCU_REGION_0 address space: 0x20000000 - 0x2FFFFFFF HOST_MCU_REGION_0 base_len can range from: ##register base_len value## 0x0 - 0x7F for HOST_MCU_REGION_0 the base address for security firewalls is 0x20000000 ( HOST_MCU_REGION_0 ) max window size is 128Kb example: worker base address: 0x20000000 current address to access: 0x20001504 region_base_address: 0x4 region_base_address_len: 0x2 --> (region_base_address + region_base_address_len) --> 0x4+0x2 -->0x6 0x20001504 --> ((0x20001504 - 0x20000000) >> 10) -->0x4 0x4 <= 0x5 < 0x6 that address falls on the region window and therefor obeys to that region set of access rules
  [12:4] BASE rw — address base with 1K granularity : address base for firewall is the the offset start address from a worker base address describing the beginning of a firewall window that has a certain access rules (R/W Permission) for each controller-id HOST_MCU address space: 0x00000000 - 0x2FFFFFFF / 0x41900000 - 0x4190FFFF HOST_MCU_REGION_1 is assigned to TCM DATA RAM HOST_MCU_REGION_1 base address can range from: ##register base value## 0x0 - 0x7F ##absolute equivalent value## 0x200000000 - 0x20001FFFF for HSM the base address for security firewalls is 0x200000000 ( M33 TCM Data RAM ) max window size is 128Kb example: worker base address: 0x200000000 current address to access: 0x20000504 region_base_address: 0x1 region_base_address_len: 0x1 0x20000504 --> ((0x20000504 - 0x200000000) >> 10) --> 0x1 0x1(base) <= 0x1(current) < 0x1(base)+0x1(len) that address falls on the region window and therefor obeys to that region set of access rules
  [2] CORENS rw — Controller Core Non Secured: '0' - access not allowed '1' - access allowed
  [1] M33S rw — Controller M33 Secured: '0' - access not allowed '1' - access allowed
  [0] M33NS rw — Controller M33 None Secured: '0' - access not allowed '1' - access allowed
0x1BC secgr_firewall_config_host_region_2 reset 0x7 — HOST MCU region 2 firewall access permission for 3 controller id : 0 - M33 Non Secured 1 - M33 Secured 2 - Core (Non Secure)
  [24:16] LEN rw — address base with 1K granularity : address base len for firewall is the offset from the region's base address indicated in the same region field describing the end of a firewall window that has a certain access rules (R/W Permission) for each controller-id HOST_MCU_REGION_0 address space: 0x20000000 - 0x2FFFFFFF HOST_MCU_REGION_0 base_len can range from: ##register base_len value## 0x0 - 0x7F for HOST_MCU_REGION_0 the base address for security firewalls is 0x20000000 ( HOST_MCU_REGION_0 ) max window size is 128Kb example: worker base address: 0x20000000 current address to access: 0x20001504 region_base_address: 0x4 region_base_address_len: 0x2 --> (region_base_address + region_base_address_len) --> 0x4+0x2 -->0x6 0x20001504 --> ((0x20001504 - 0x20000000) >> 10) -->0x4 0x4 <= 0x5 < 0x6 that address falls on the region window and therefor obeys to that region set of access rules
  [12:4] BASE rw — address base with 1K granularity : address base for firewall is the the offset start address from a worker base address describing the beginning of a firewall window that has a certain access rules (R/W Permission) for each controller-id HOST_MCU address space: 0x00000000 - 0x2FFFFFFF / 0x41900000 - 0x4190FFFF HOST_MCU_REGION_2 is assigned to TCM DATA RAM HOST_MCU_REGION_2 base address can range from: ##register base value## 0x0 - 0x1A0 ##absolute equivalent value## 0x280000000 - 0x280068000 for HOST_MCU_REGION_2 the base address for security firewalls is 0x280000000 ( M33 Data RAM ) max window size is 416Kb (depending on the MEMSS mode) example: worker base address: 0x280000000 current address to access: 0x28000504 region_base_address: 0x1 region_base_address_len: 0x1 0x28000504 --> ((0x28000504 - 0x280000000) >> 10) --> 0x1 0x1(base) <= 0x1(current) < 0x1(base)+0x1(len) that address falls on the region window and therefor obeys to that region set of access rules
  [2] CORENS rw — Controller Core Non Secured: '0' - access not allowed '1' - access allowed
  [1] M33S rw — Controller M33 Secured: '0' - access not allowed '1' - access allowed
  [0] M33NS rw — Controller M33 None Secured: '0' - access not allowed '1' - access allowed
